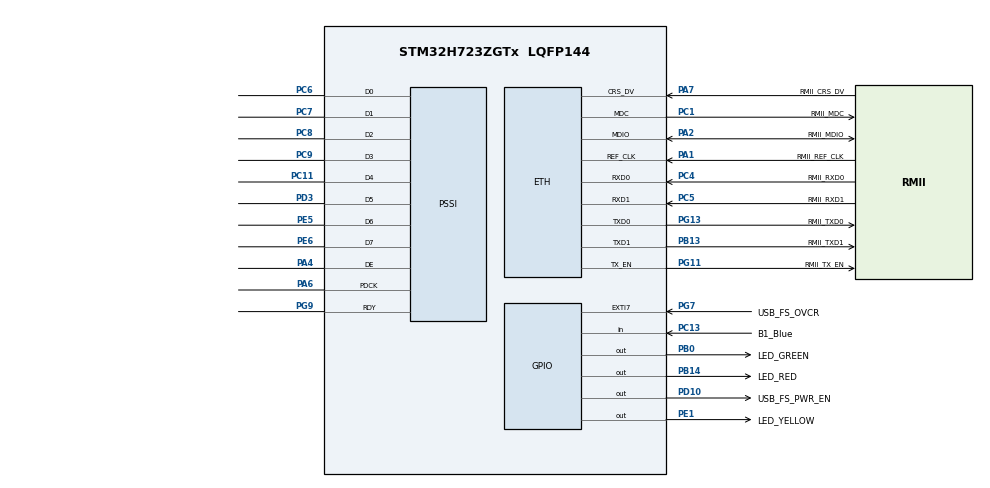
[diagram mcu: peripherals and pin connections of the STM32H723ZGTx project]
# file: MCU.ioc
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CORTEX_M7.AccessPermission-Cortex_Memory_Protection_Unit_Region0_Settings=MPU_REGION_NO_ACCESS
CORTEX_M7.AccessPermission-Cortex_Memory_Protection_Unit_Region1_Settings=MPU_REGION_FULL_ACCESS
CORTEX_M7.AccessPermission-Cortex_Memory_Protection_Unit_Region2_Settings=MPU_REGION_FULL_ACCESS
CORTEX_M7.AccessPermission_S-Cortex_Memory_Protection_Unit_Region1_Settings_S=MPU_REGION_FULL_ACCESS
CORTEX_M7.AccessPermission_S-Cortex_Memory_Protection_Unit_Region2_Settings_S=MPU_REGION_FULL_ACCESS
CORTEX_M7.BaseAddress-Cortex_Memory_Protection_Unit_Region0_Settings=0x0
CORTEX_M7.BaseAddress-Cortex_Memory_Protection_Unit_Region1_Settings=0x30000000
CORTEX_M7.BaseAddress-Cortex_Memory_Protection_Unit_Region2_Settings=0x30004000
CORTEX_M7.BaseAddress_S-Cortex_Memory_Protection_Unit_Region1_Settings_S=0x30000000
CORTEX_M7.BaseAddress_S-Cortex_Memory_Protection_Unit_Region2_Settings_S=0x30000000
CORTEX_M7.CPU_DCache=Enabled
CORTEX_M7.CPU_ICache=Enabled
CORTEX_M7.DisableExec-Cortex_Memory_Protection_Unit_Region0_Settings=MPU_INSTRUCTION_ACCESS_DISABLE
CORTEX_M7.DisableExec-Cortex_Memory_Protection_Unit_Region1_Settings=MPU_INSTRUCTION_ACCESS_ENABLE
CORTEX_M7.DisableExec_S-Cortex_Memory_Protection_Unit_Region1_Settings_S=MPU_INSTRUCTION_ACCESS_DISABLE
CORTEX_M7.DisableExec_S-Cortex_Memory_Protection_Unit_Region2_Settings_S=MPU_INSTRUCTION_ACCESS_DISABLE
CORTEX_M7.Enable-Cortex_Memory_Protection_Unit_Region0_Settings=MPU_REGION_ENABLE
CORTEX_M7.Enable-Cortex_Memory_Protection_Unit_Region1_Settings=MPU_REGION_ENABLE
CORTEX_M7.Enable-Cortex_Memory_Protection_Unit_Region2_Settings=MPU_REGION_ENABLE
CORTEX_M7.Enable_S-Cortex_Memory_Protection_Unit_Region1_Settings_S=MPU_REGION_ENABLE
CORTEX_M7.Enable_S-Cortex_Memory_Protection_Unit_Region2_Settings_S=MPU_REGION_ENABLE
CORTEX_M7.IsBufferable-Cortex_Memory_Protection_Unit_Region0_Settings=MPU_ACCESS_BUFFERABLE
CORTEX_M7.IsBufferable-Cortex_Memory_Protection_Unit_Region1_Settings=MPU_ACCESS_BUFFERABLE
CORTEX_M7.IsBufferable_S-Cortex_Memory_Protection_Unit_Region2_Settings_S=MPU_ACCESS_BUFFERABLE
CORTEX_M7.IsShareable-Cortex_Memory_Protection_Unit_Region0_Settings=MPU_ACCESS_SHAREABLE
CORTEX_M7.IsShareable-Cortex_Memory_Protection_Unit_Region1_Settings=MPU_ACCESS_NOT_SHAREABLE
CORTEX_M7.IsShareable-Cortex_Memory_Protection_Unit_Region2_Settings=MPU_ACCESS_SHAREABLE
CORTEX_M7.IsShareable_S-Cortex_Memory_Protection_Unit_Region2_Settings_S=MPU_ACCESS_SHAREABLE
CORTEX_M7.MPU_Control=MPU_PRIVILEGED_DEFAULT
CORTEX_M7.Size-Cortex_Memory_Protection_Unit_Region0_Settings=MPU_REGION_SIZE_4GB
CORTEX_M7.Size-Cortex_Memory_Protection_Unit_Region1_Settings=MPU_REGION_SIZE_1KB
CORTEX_M7.Size-Cortex_Memory_Protection_Unit_Region2_Settings=MPU_REGION_SIZE_16KB
CORTEX_M7.Size_S-Cortex_Memory_Protection_Unit_Region1_Settings_S=MPU_REGION_SIZE_1KB
CORTEX_M7.Size_S-Cortex_Memory_Protection_Unit_Region2_Settings_S=MPU_REGION_SIZE_512B
CORTEX_M7.SubRegionDisable-Cortex_Memory_Protection_Unit_Region0_Settings=0x87
CORTEX_M7.TypeExtField-Cortex_Memory_Protection_Unit_Region0_Settings=MPU_TEX_LEVEL0
CORTEX_M7.TypeExtField-Cortex_Memory_Protection_Unit_Region2_Settings=MPU_TEX_LEVEL1
CORTEX_M7.TypeExtField_S-Cortex_Memory_Protection_Unit_Region1_Settings_S=MPU_TEX_LEVEL0
CORTEX_M7.default_mode_Activation=0
ETH.MediaInterface=HAL_ETH_RMII_MODE
FREERTOS.Tasks01=defaultTask,24,512,StartDefaultTask,Default,NULL,Dynamic,NULL,NULL
FREERTOS.configUSE_NEWLIB_REENTRANT=1
LWIP.BSP.number=1
LWIP.IP_ADDRESS=192.168.001.124
LWIP.LWIP_DHCP=0
LWIP.LWIP_RAM_HEAP_POINTER=0x30004000
LWIP.MEM_SIZE=1024*14
LWIP.NETMASK_ADDRESS=255.255.255.000
LWIP.TCP_MSS=1460
LWIP.TCP_SND_BUF=5840
LWIP.TCP_SND_QUEUELEN=16
LWIP.Version=v2.1.2_Cube
LWIP0.BSP.STBoard=false
LWIP0.BSP.api=BSP_COMPONENT_DRIVER
LWIP0.BSP.component=LAN8742
LWIP0.BSP.instance=LAN8742
LWIP0.BSP.name=Driver_PHY
LWIP0.BSP.semaphore=S_LAN8742
LWIP0.BSP.solution=LAN8742
Mcu.Family=STM32H7
Mcu.Name=STM32H723ZGTx
Mcu.Package=LQFP144
NVIC.ETH_IRQn=true\:5\:0\:false\:false\:true\:true\:true\:true\:true
NVIC.PriorityGroup=NVIC_PRIORITYGROUP_4
NVIC.TIM6_DAC_IRQn=true\:15\:0\:false\:false\:true\:false\:false\:true\:true
NVIC.TimeBase=TIM6_DAC_IRQn
NVIC.TimeBaseIP=TIM6
PA1.GPIO_Label=RMII_REF_CLK
PA1.GPIO_Speed=GPIO_SPEED_FREQ_VERY_HIGH
PA1.Mode=RMII
PA1.Signal=ETH_REF_CLK
PA13(JTMS/SWDIO).GPIO_Label=SWDIO
PA13(JTMS/SWDIO).Mode=Trace_Asynchronous_SW
PA13(JTMS/SWDIO).Signal=DEBUG_JTMS-SWDIO
PA14(JTCK/SWCLK).GPIO_Label=SWCLK
PA14(JTCK/SWCLK).Mode=Trace_Asynchronous_SW
PA14(JTCK/SWCLK).Signal=DEBUG_JTCK-SWCLK
PA2.GPIO_Label=RMII_MDIO
PA2.GPIO_Speed=GPIO_SPEED_FREQ_VERY_HIGH
PA2.Mode=RMII
PA2.Signal=ETH_MDIO
PA4.GPIO_Speed=GPIO_SPEED_FREQ_HIGH
PA4.Mode=PSSI_8
PA4.Signal=PSSI_DE
PA6.GPIO_Speed=GPIO_SPEED_FREQ_HIGH
PA6.Mode=PSSI_8
PA6.Signal=PSSI_PDCK
PA7.GPIO_Label=RMII_CRS_DV
PA7.GPIO_Speed=GPIO_SPEED_FREQ_VERY_HIGH
PA7.Mode=RMII
PA7.Signal=ETH_CRS_DV
PB0.GPIO_Label=LED_GREEN
PB0.Signal=GPIO_Output
PB13.GPIO_Label=RMII_TXD1
PB13.GPIO_Speed=GPIO_SPEED_FREQ_VERY_HIGH
PB13.Mode=RMII
PB13.Signal=ETH_TXD1
PB14.GPIO_Label=LED_RED
PB14.Signal=GPIO_Output
PB3(JTDO/TRACESWO).GPIO_Label=SWO
PB3(JTDO/TRACESWO).Mode=Trace_Asynchronous_SW
PB3(JTDO/TRACESWO).Signal=DEBUG_JTDO-SWO
PC1.GPIO_Label=RMII_MDC
PC1.Mode=RMII
PC1.Signal=ETH_MDC
PC11.GPIO_Speed=GPIO_SPEED_FREQ_HIGH
PC11.Mode=PSSI_8
PC11.Signal=PSSI_D4
PC13.GPIO_Label=B1_Blue
PC13.Signal=GPIO_Input
PC4.GPIO_Label=RMII_RXD0
PC4.GPIO_Speed=GPIO_SPEED_FREQ_VERY_HIGH
PC4.Mode=RMII
PC4.Signal=ETH_RXD0
PC5.GPIO_Label=RMII_RXD1
PC5.GPIO_Speed=GPIO_SPEED_FREQ_VERY_HIGH
PC5.Mode=RMII
PC5.Signal=ETH_RXD1
PC6.Mode=PSSI_8
PC6.Signal=PSSI_D0
PC7.Mode=PSSI_8
PC7.Signal=PSSI_D1
PC8.Mode=PSSI_8
PC8.Signal=PSSI_D2
PC9.Mode=PSSI_8
PC9.Signal=PSSI_D3
PD10.GPIO_Label=USB_FS_PWR_EN
PD10.Signal=GPIO_Output
PD3.Mode=PSSI_8
PD3.Signal=PSSI_D5
PE1.GPIO_Label=LED_YELLOW
PE1.Signal=GPIO_Output
PE5.Mode=PSSI_8
PE5.Signal=PSSI_D6
PE6.Mode=PSSI_8
PE6.Signal=PSSI_D7
PG11.GPIO_Label=RMII_TX_EN
PG11.GPIO_Speed=GPIO_SPEED_FREQ_VERY_HIGH
PG11.Mode=RMII
PG11.Signal=ETH_TX_EN
PG13.GPIO_Label=RMII_TXD0
PG13.GPIO_Speed=GPIO_SPEED_FREQ_VERY_HIGH
PG13.Mode=RMII
PG13.Signal=ETH_TXD0
PG7.GPIO_Label=USB_FS_OVCR
PG7.Signal=GPXTI7
PG9.Mode=PSSI_8
PG9.Signal=PSSI_RDY
PH0-OSC_IN.GPIO_Label=MCO
PH0-OSC_IN.Mode=HSE-External-Clock-Source
PH0-OSC_IN.Signal=RCC_OSC_IN
PSSI.BusWidth=HAL_PSSI_8LINES
PSSI.ClockPolarity=HAL_PSSI_RISING_EDGE
PSSI.ControlSignal=HAL_PSSI_DE_ENABLE
ProjectManager.HeapSize=0x200
ProjectManager.StackSize=0x400
ProjectManager.TargetToolchain=STM32CubeIDE
RCC.ADCFreq_Value=76000000
RCC.APB1Freq_Value=137500000
RCC.APB2Freq_Value=137500000
RCC.APB3Freq_Value=137500000
RCC.APB4Freq_Value=137500000
RCC.CortexFreq_Value=550000000
RCC.D1PPRE=RCC_APB3_DIV2
RCC.D2PPRE1=RCC_APB1_DIV2
RCC.D2PPRE2=RCC_APB2_DIV2
RCC.D3PPRE=RCC_APB4_DIV2
RCC.DIVM1=4
RCC.DIVM2=1
RCC.DIVN1=275
RCC.DIVN2=19
RCC.DIVP1=1
RCC.DIVQ1=4
RCC.HCLKFreq_Value=275000000
RCC.HPRE=RCC_HCLK_DIV2
RCC.HSE_VALUE=8000000
RCC.PLLFRACN=0
RCC.PLLSourceVirtual=RCC_PLLSOURCE_HSE
RCC.SYSCLKFreq_VALUE=550000000
RCC.SYSCLKSource=RCC_SYSCLKSOURCE_PLLCLK
RCC.USBCLockSelection=RCC_USBCLKSOURCE_HSI48
RCC.USBFreq_Value=48000000
VP_FREERTOS_VS_CMSIS_V2.Mode=CMSIS_V2
VP_LWIP_VS_Enabled.Mode=Enabled
VP_SYS_VS_tim6.Mode=TIM6
board=NUCLEO-H723ZG

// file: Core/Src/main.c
/* USER CODE BEGIN Header */
/**
  ******************************************************************************
  * @file           : main.c
  * @brief          : Main program body
  ******************************************************************************
  * @attention
  *
  * Copyright (c) 2023 STMicroelectronics.
  * All rights reserved.
  *
  * This software is licensed under terms that can be found in the LICENSE file
  * in the root directory of this software component.
  * If no LICENSE file comes with this software, it is provided AS-IS.
  *
  ******************************************************************************
  */
/* USER CODE END Header */
#include "main.h"
#include "cmsis_os.h"
#include "lwip.h"

/* USER CODE BEGIN Includes */
#include "scpi_server.h"
/* USER CODE END Includes */

PSSI_HandleTypeDef hpssi;

/* Definitions for defaultTask */
osThreadId_t defaultTaskHandle;
const osThreadAttr_t defaultTask_attributes = {
  .name = "defaultTask",
  .stack_size = 512 * 4,
  .priority = (osPriority_t) osPriorityNormal,
};
/* USER CODE BEGIN PV */

uint32_t PSSI_HAL_PSSI_TransmitComplete_count = 0;
uint32_t PSSI_HAL_PSSI_ReceiveComplete_count = 0;
uint32_t PSSI_HAL_PSSI_ErrorCallback_count = 0;

/* USER CODE END PV */

void SystemClock_Config(void);
static void MPU_Config(void);
static void MX_GPIO_Init(void);
static void MX_PSSI_Init(void);
void StartDefaultTask(void *argument);

/* USER CODE BEGIN 0 */
/*
void HAL_PSSI_RxCpltCallback(PSSI_HandleTypeDef *hpssi)
{
  PSSI_HAL_PSSI_ReceiveComplete_count++;
}

void HAL_PSSI_TxCpltCallback(PSSI_HandleTypeDef *hpssi)
{
  PSSI_HAL_PSSI_TransmitComplete_count++;
}

void HAL_PSSI_ErrorCallback(PSSI_HandleTypeDef *hpssi)
{
  PSSI_HAL_PSSI_ErrorCallback_count++;
}
*/
/* USER CODE END 0 */

int main(void)
{

  /* MPU Configuration--------------------------------------------------------*/
  MPU_Config();

  /* Enable I-Cache---------------------------------------------------------*/
  SCB_EnableICache();

  /* Enable D-Cache---------------------------------------------------------*/
  SCB_EnableDCache();

  /* MCU Configuration--------------------------------------------------------*/

  /* Reset of all peripherals, Initializes the Flash interface and the Systick. */
  HAL_Init();

  /* Configure the system clock */
  SystemClock_Config();

  /* Initialize all configured peripherals */
  MX_GPIO_Init();
  MX_PSSI_Init();

  /* Init scheduler */
  osKernelInitialize();

  /* Create the thread(s) */
  /* creation of defaultTask */
  defaultTaskHandle = osThreadNew(StartDefaultTask, NULL, &defaultTask_attributes);

  /* Start scheduler */
  osKernelStart();
  /* We should never get here as control is now taken by the scheduler */
  /* Infinite loop */
  while (1)
  {

  }
}

void SystemClock_Config(void)
{
  RCC_OscInitTypeDef RCC_OscInitStruct = {0};
  RCC_ClkInitTypeDef RCC_ClkInitStruct = {0};

  /** Supply configuration update enable
  */
  HAL_PWREx_ConfigSupply(PWR_LDO_SUPPLY);

  /** Configure the main internal regulator output voltage
  */
  __HAL_PWR_VOLTAGESCALING_CONFIG(PWR_REGULATOR_VOLTAGE_SCALE0);

  while(!__HAL_PWR_GET_FLAG(PWR_FLAG_VOSRDY)) {}

  /** Initializes the RCC Oscillators according to the specified parameters
  * in the RCC_OscInitTypeDef structure.
  */
  RCC_OscInitStruct.OscillatorType = RCC_OSCILLATORTYPE_HSE;
  RCC_OscInitStruct.HSEState = RCC_HSE_BYPASS;
  RCC_OscInitStruct.PLL.PLLState = RCC_PLL_ON;
  RCC_OscInitStruct.PLL.PLLSource = RCC_PLLSOURCE_HSE;
  RCC_OscInitStruct.PLL.PLLM = 4;
  RCC_OscInitStruct.PLL.PLLN = 275;
  RCC_OscInitStruct.PLL.PLLP = 1;
  RCC_OscInitStruct.PLL.PLLQ = 4;
  RCC_OscInitStruct.PLL.PLLR = 2;
  RCC_OscInitStruct.PLL.PLLRGE = RCC_PLL1VCIRANGE_1;
  RCC_OscInitStruct.PLL.PLLVCOSEL = RCC_PLL1VCOWIDE;
  RCC_OscInitStruct.PLL.PLLFRACN = 0;
  if (HAL_RCC_OscConfig(&RCC_OscInitStruct) != HAL_OK)
  {
    Error_Handler();
  }

  /** Initializes the CPU, AHB and APB buses clocks
  */
  RCC_ClkInitStruct.ClockType = RCC_CLOCKTYPE_HCLK|RCC_CLOCKTYPE_SYSCLK
                              |RCC_CLOCKTYPE_PCLK1|RCC_CLOCKTYPE_PCLK2
                              |RCC_CLOCKTYPE_D3PCLK1|RCC_CLOCKTYPE_D1PCLK1;
  RCC_ClkInitStruct.SYSCLKSource = RCC_SYSCLKSOURCE_PLLCLK;
  RCC_ClkInitStruct.SYSCLKDivider = RCC_SYSCLK_DIV1;
  RCC_ClkInitStruct.AHBCLKDivider = RCC_HCLK_DIV2;
  RCC_ClkInitStruct.APB3CLKDivider = RCC_APB3_DIV2;
  RCC_ClkInitStruct.APB1CLKDivider = RCC_APB1_DIV2;
  RCC_ClkInitStruct.APB2CLKDivider = RCC_APB2_DIV2;
  RCC_ClkInitStruct.APB4CLKDivider = RCC_APB4_DIV2;

  if (HAL_RCC_ClockConfig(&RCC_ClkInitStruct, FLASH_LATENCY_3) != HAL_OK)
  {
    Error_Handler();
  }
}

static void MX_PSSI_Init(void)
{

  hpssi.Instance = PSSI;
  hpssi.Init.DataWidth = HAL_PSSI_8BITS;
  hpssi.Init.BusWidth = HAL_PSSI_8LINES;
  hpssi.Init.ControlSignal = HAL_PSSI_DE_ENABLE;
  hpssi.Init.ClockPolarity = HAL_PSSI_RISING_EDGE;
  hpssi.Init.DataEnablePolarity = HAL_PSSI_DEPOL_ACTIVE_LOW;
  hpssi.Init.ReadyPolarity = HAL_PSSI_RDYPOL_ACTIVE_LOW;
  if (HAL_PSSI_Init(&hpssi) != HAL_OK)
  {
    Error_Handler();
  }

}

static void MX_GPIO_Init(void)
{
  GPIO_InitTypeDef GPIO_InitStruct = {0};

  /* GPIO Ports Clock Enable */
  __HAL_RCC_GPIOE_CLK_ENABLE();
  __HAL_RCC_GPIOC_CLK_ENABLE();
  __HAL_RCC_GPIOH_CLK_ENABLE();
  __HAL_RCC_GPIOA_CLK_ENABLE();
  __HAL_RCC_GPIOB_CLK_ENABLE();
  __HAL_RCC_GPIOD_CLK_ENABLE();
  __HAL_RCC_GPIOG_CLK_ENABLE();

  /*Configure GPIO pin Output Level */
  HAL_GPIO_WritePin(GPIOB, LED_GREEN_Pin|LED_RED_Pin, GPIO_PIN_RESET);

  /*Configure GPIO pin Output Level */
  HAL_GPIO_WritePin(USB_FS_PWR_EN_GPIO_Port, USB_FS_PWR_EN_Pin, GPIO_PIN_RESET);

  /*Configure GPIO pin Output Level */
  HAL_GPIO_WritePin(LED_YELLOW_GPIO_Port, LED_YELLOW_Pin, GPIO_PIN_RESET);

  /*Configure GPIO pin : B1_Blue_Pin */
  GPIO_InitStruct.Pin = B1_Blue_Pin;
  GPIO_InitStruct.Mode = GPIO_MODE_INPUT;
  GPIO_InitStruct.Pull = GPIO_NOPULL;
  HAL_GPIO_Init(B1_Blue_GPIO_Port, &GPIO_InitStruct);

  /*Configure GPIO pins : LED_GREEN_Pin LED_RED_Pin */
  GPIO_InitStruct.Pin = LED_GREEN_Pin|LED_RED_Pin;
  GPIO_InitStruct.Mode = GPIO_MODE_OUTPUT_PP;
  GPIO_InitStruct.Pull = GPIO_NOPULL;
  GPIO_InitStruct.Speed = GPIO_SPEED_FREQ_LOW;
  HAL_GPIO_Init(GPIOB, &GPIO_InitStruct);

  /*Configure GPIO pin : USB_FS_PWR_EN_Pin */
  GPIO_InitStruct.Pin = USB_FS_PWR_EN_Pin;
  GPIO_InitStruct.Mode = GPIO_MODE_OUTPUT_PP;
  GPIO_InitStruct.Pull = GPIO_NOPULL;
  GPIO_InitStruct.Speed = GPIO_SPEED_FREQ_LOW;
  HAL_GPIO_Init(USB_FS_PWR_EN_GPIO_Port, &GPIO_InitStruct);

  /*Configure GPIO pin : USB_FS_OVCR_Pin */
  GPIO_InitStruct.Pin = USB_FS_OVCR_Pin;
  GPIO_InitStruct.Mode = GPIO_MODE_IT_RISING;
  GPIO_InitStruct.Pull = GPIO_NOPULL;
  HAL_GPIO_Init(USB_FS_OVCR_GPIO_Port, &GPIO_InitStruct);

  /*Configure GPIO pin : LED_YELLOW_Pin */
  GPIO_InitStruct.Pin = LED_YELLOW_Pin;
  GPIO_InitStruct.Mode = GPIO_MODE_OUTPUT_PP;
  GPIO_InitStruct.Pull = GPIO_NOPULL;
  GPIO_InitStruct.Speed = GPIO_SPEED_FREQ_LOW;
  HAL_GPIO_Init(LED_YELLOW_GPIO_Port, &GPIO_InitStruct);

}

void StartDefaultTask(void *argument)
{
  /* init code for LWIP */
  MX_LWIP_Init();
  /* USER CODE BEGIN 5 */
  osDelay(pdMS_TO_TICKS(100));
  SCPI_ServerInit();
  /* Infinite loop */
  for(;;)
  {
    osDelay(1);
  }
  /* USER CODE END 5 */
}

/* MPU Configuration */

void MPU_Config(void)
{
  MPU_Region_InitTypeDef MPU_InitStruct = {0};

  /* Disables the MPU */
  HAL_MPU_Disable();

  /** Initializes and configures the Region and the memory to be protected
  */
  MPU_InitStruct.Enable = MPU_REGION_ENABLE;
  MPU_InitStruct.Number = MPU_REGION_NUMBER0;
  MPU_InitStruct.BaseAddress = 0x0;
  MPU_InitStruct.Size = MPU_REGION_SIZE_4GB;
  MPU_InitStruct.SubRegionDisable = 0x87;
  MPU_InitStruct.TypeExtField = MPU_TEX_LEVEL0;
  MPU_InitStruct.AccessPermission = MPU_REGION_NO_ACCESS;
  MPU_InitStruct.DisableExec = MPU_INSTRUCTION_ACCESS_DISABLE;
  MPU_InitStruct.IsShareable = MPU_ACCESS_SHAREABLE;
  MPU_InitStruct.IsCacheable = MPU_ACCESS_NOT_CACHEABLE;
  MPU_InitStruct.IsBufferable = MPU_ACCESS_BUFFERABLE;

  HAL_MPU_ConfigRegion(&MPU_InitStruct);

  /** Initializes and configures the Region and the memory to be protected
  */
  MPU_InitStruct.Number = MPU_REGION_NUMBER1;
  MPU_InitStruct.BaseAddress = 0x30000000;
  MPU_InitStruct.Size = MPU_REGION_SIZE_1KB;
  MPU_InitStruct.SubRegionDisable = 0x0;
  MPU_InitStruct.AccessPermission = MPU_REGION_FULL_ACCESS;
  MPU_InitStruct.DisableExec = MPU_INSTRUCTION_ACCESS_ENABLE;
  MPU_InitStruct.IsShareable = MPU_ACCESS_NOT_SHAREABLE;

  HAL_MPU_ConfigRegion(&MPU_InitStruct);

  /** Initializes and configures the Region and the memory to be protected
  */
  MPU_InitStruct.Number = MPU_REGION_NUMBER2;
  MPU_InitStruct.BaseAddress = 0x30004000;
  MPU_InitStruct.Size = MPU_REGION_SIZE_16KB;
  MPU_InitStruct.TypeExtField = MPU_TEX_LEVEL1;
  MPU_InitStruct.IsShareable = MPU_ACCESS_SHAREABLE;
  MPU_InitStruct.IsBufferable = MPU_ACCESS_NOT_BUFFERABLE;

  HAL_MPU_ConfigRegion(&MPU_InitStruct);
  /* Enables the MPU */
  HAL_MPU_Enable(MPU_PRIVILEGED_DEFAULT);

}

void HAL_TIM_PeriodElapsedCallback(TIM_HandleTypeDef *htim)
{
  if (htim->Instance == TIM6) {
    HAL_IncTick();
  }
}

void Error_Handler(void)
{
  /* USER CODE BEGIN Error_Handler_Debug */
	HAL_GPIO_WritePin(LED_RED_GPIO_Port, LED_RED_Pin, GPIO_PIN_SET);
  /* User can add his own implementation to report the HAL error return state */
  __disable_irq();
  while (1)
  {
  }
  /* USER CODE END Error_Handler_Debug */
}
